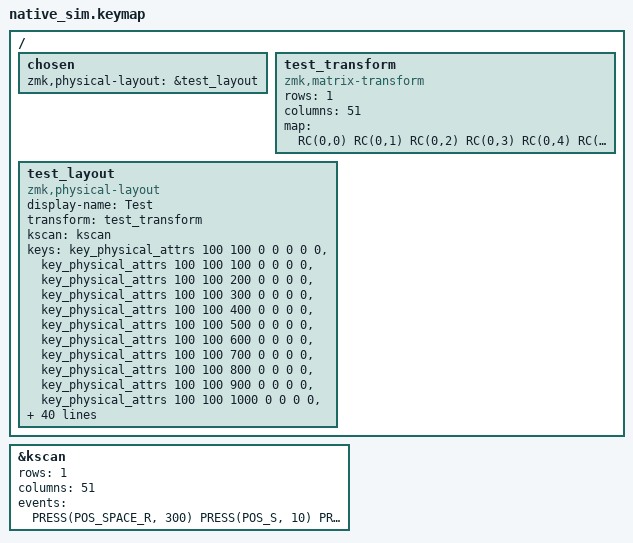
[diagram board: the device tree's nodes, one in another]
#include "../../config/coron.keymap"
#include "../coron_test.h"

/* Studio は物理レイアウトを必須とするので、モック kscan に合わせた 1 行 51 列のレイアウトを与える */
#include <physical_layouts.dtsi>
#include <dt-bindings/zmk/matrix_transform.h>

/ {
    chosen {
        zmk,physical-layout = &test_layout;
    };

    test_transform: test_transform {
        compatible = "zmk,matrix-transform";
        rows = <1>;
        columns = <51>;
        map = <RC(0,0) RC(0,1) RC(0,2) RC(0,3) RC(0,4) RC(0,5) RC(0,6) RC(0,7) RC(0,8) RC(0,9) RC(0,10) RC(0,11) RC(0,12) RC(0,13) RC(0,14) RC(0,15) RC(0,16) RC(0,17) RC(0,18) RC(0,19) RC(0,20) RC(0,21) RC(0,22) RC(0,23) RC(0,24) RC(0,25) RC(0,26) RC(0,27) RC(0,28) RC(0,29) RC(0,30) RC(0,31) RC(0,32) RC(0,33) RC(0,34) RC(0,35) RC(0,36) RC(0,37) RC(0,38) RC(0,39) RC(0,40) RC(0,41) RC(0,42) RC(0,43) RC(0,44) RC(0,45) RC(0,46) RC(0,47) RC(0,48) RC(0,49) RC(0,50)>;
    };

    test_layout: test_layout {
        compatible = "zmk,physical-layout";
        display-name = "Test";
        transform = <&test_transform>;
        kscan = <&kscan>;
        keys
            = <&key_physical_attrs 100 100 0 0 0 0 0>
            , <&key_physical_attrs 100 100 100 0 0 0 0>
            , <&key_physical_attrs 100 100 200 0 0 0 0>
            , <&key_physical_attrs 100 100 300 0 0 0 0>
            , <&key_physical_attrs 100 100 400 0 0 0 0>
            , <&key_physical_attrs 100 100 500 0 0 0 0>
            , <&key_physical_attrs 100 100 600 0 0 0 0>
            , <&key_physical_attrs 100 100 700 0 0 0 0>
            , <&key_physical_attrs 100 100 800 0 0 0 0>
            , <&key_physical_attrs 100 100 900 0 0 0 0>
            , <&key_physical_attrs 100 100 1000 0 0 0 0>
            , <&key_physical_attrs 100 100 1100 0 0 0 0>
            , <&key_physical_attrs 100 100 1200 0 0 0 0>
            , <&key_physical_attrs 100 100 1300 0 0 0 0>
            , <&key_physical_attrs 100 100 1400 0 0 0 0>
            , <&key_physical_attrs 100 100 1500 0 0 0 0>
            , <&key_physical_attrs 100 100 1600 0 0 0 0>
            , <&key_physical_attrs 100 100 1700 0 0 0 0>
            , <&key_physical_attrs 100 100 1800 0 0 0 0>
            , <&key_physical_attrs 100 100 1900 0 0 0 0>
            , <&key_physical_attrs 100 100 2000 0 0 0 0>
            , <&key_physical_attrs 100 100 2100 0 0 0 0>
            , <&key_physical_attrs 100 100 2200 0 0 0 0>
            , <&key_physical_attrs 100 100 2300 0 0 0 0>
            , <&key_physical_attrs 100 100 2400 0 0 0 0>
            , <&key_physical_attrs 100 100 2500 0 0 0 0>
            , <&key_physical_attrs 100 100 2600 0 0 0 0>
            , <&key_physical_attrs 100 100 2700 0 0 0 0>
            , <&key_physical_attrs 100 100 2800 0 0 0 0>
            , <&key_physical_attrs 100 100 2900 0 0 0 0>
            , <&key_physical_attrs 100 100 3000 0 0 0 0>
            , <&key_physical_attrs 100 100 3100 0 0 0 0>
            , <&key_physical_attrs 100 100 3200 0 0 0 0>
            , <&key_physical_attrs 100 100 3300 0 0 0 0>
            , <&key_physical_attrs 100 100 3400 0 0 0 0>
            , <&key_physical_attrs 100 100 3500 0 0 0 0>
            , <&key_physical_attrs 100 100 3600 0 0 0 0>
            , <&key_physical_attrs 100 100 3700 0 0 0 0>
            , <&key_physical_attrs 100 100 3800 0 0 0 0>
            , <&key_physical_attrs 100 100 3900 0 0 0 0>
            , <&key_physical_attrs 100 100 4000 0 0 0 0>
            , <&key_physical_attrs 100 100 4100 0 0 0 0>
            , <&key_physical_attrs 100 100 4200 0 0 0 0>
            , <&key_physical_attrs 100 100 4300 0 0 0 0>
            , <&key_physical_attrs 100 100 4400 0 0 0 0>
            , <&key_physical_attrs 100 100 4500 0 0 0 0>
            , <&key_physical_attrs 100 100 4600 0 0 0 0>
            , <&key_physical_attrs 100 100 4700 0 0 0 0>
            , <&key_physical_attrs 100 100 4800 0 0 0 0>
            , <&key_physical_attrs 100 100 4900 0 0 0 0>
            , <&key_physical_attrs 100 100 5000 0 0 0 0>
            ;
    };
};

&kscan {
    rows = <1>;
    columns = <51>;

    events = <
        /* ホールドが確定してから 4 つのコンボを順に押す */
        PRESS(POS_SPACE_R, 300)
        PRESS(POS_S, 10) PRESS(POS_D, 30) RELEASE(POS_S, 10) RELEASE(POS_D, 100)
        PRESS(POS_D, 10) PRESS(POS_F, 30) RELEASE(POS_D, 10) RELEASE(POS_F, 100)
        PRESS(POS_J, 10) PRESS(POS_K, 30) RELEASE(POS_J, 10) RELEASE(POS_K, 100)
        PRESS(POS_K, 10) PRESS(POS_L, 30) RELEASE(POS_K, 10) RELEASE(POS_L, 100)
        RELEASE(POS_SPACE_R, 300)
        /* サムキーを押した直後にコンボを押し、コンボのキーを先に離す */
        PRESS(POS_SPACE_R, 20) PRESS(POS_S, 10) PRESS(POS_D, 30) RELEASE(POS_S, 10) RELEASE(POS_D, 10) RELEASE(POS_SPACE_R, 300)
        PRESS(POS_SPACE_R, 20) PRESS(POS_K, 10) PRESS(POS_L, 30) RELEASE(POS_L, 10) RELEASE(POS_K, 10) RELEASE(POS_SPACE_R, 100)
    >;
};
